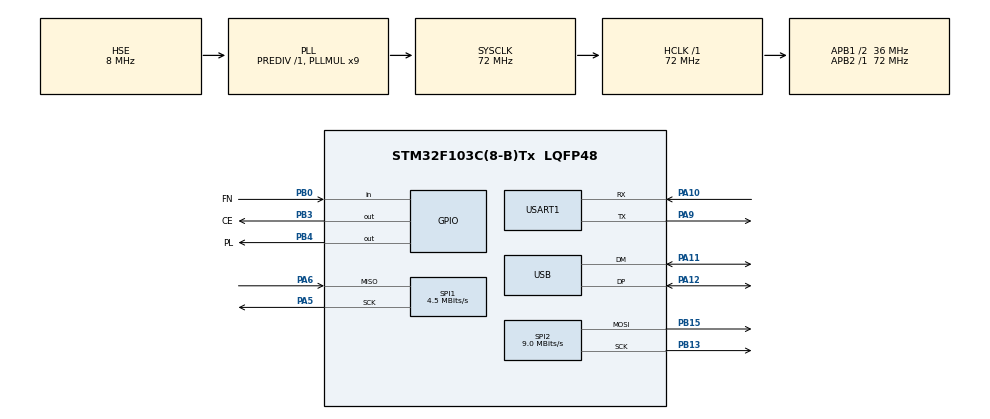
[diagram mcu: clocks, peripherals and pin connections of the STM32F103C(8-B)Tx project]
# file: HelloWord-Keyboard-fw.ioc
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Dma.Request0=SPI2_TX
Dma.Request1=SPI1_RX
Dma.SPI1_RX.1.Direction=DMA_PERIPH_TO_MEMORY
Dma.SPI1_RX.1.Instance=DMA1_Channel2
Dma.SPI1_RX.1.MemDataAlignment=DMA_MDATAALIGN_BYTE
Dma.SPI1_RX.1.MemInc=DMA_MINC_ENABLE
Dma.SPI1_RX.1.Mode=DMA_NORMAL
Dma.SPI1_RX.1.PeriphDataAlignment=DMA_PDATAALIGN_BYTE
Dma.SPI1_RX.1.PeriphInc=DMA_PINC_DISABLE
Dma.SPI1_RX.1.Priority=DMA_PRIORITY_MEDIUM
Dma.SPI2_TX.0.Direction=DMA_MEMORY_TO_PERIPH
Dma.SPI2_TX.0.Instance=DMA1_Channel5
Dma.SPI2_TX.0.MemDataAlignment=DMA_MDATAALIGN_BYTE
Dma.SPI2_TX.0.MemInc=DMA_MINC_ENABLE
Dma.SPI2_TX.0.Mode=DMA_NORMAL
Dma.SPI2_TX.0.PeriphDataAlignment=DMA_PDATAALIGN_BYTE
Dma.SPI2_TX.0.PeriphInc=DMA_PINC_DISABLE
Dma.SPI2_TX.0.Priority=DMA_PRIORITY_MEDIUM
Mcu.Family=STM32F1
Mcu.Name=STM32F103C(8-B)Tx
Mcu.Package=LQFP48
NVIC.DMA1_Channel2_IRQn=true\:2\:0\:true\:false\:true\:false\:true\:true
NVIC.DMA1_Channel5_IRQn=true\:2\:1\:true\:false\:true\:false\:true\:true
NVIC.PVD_IRQn=true\:0\:0\:false\:false\:true\:true\:true\:true
NVIC.PriorityGroup=NVIC_PRIORITYGROUP_2
NVIC.SPI1_IRQn=true\:1\:0\:true\:false\:true\:true\:true\:true
NVIC.SPI2_IRQn=true\:1\:1\:true\:false\:true\:true\:true\:true
NVIC.TIM4_IRQn=true\:0\:1\:false\:false\:true\:true\:true\:true
NVIC.USART1_IRQn=true\:0\:0\:true\:false\:true\:true\:true\:true
NVIC.USB_LP_CAN1_RX0_IRQn=true\:0\:0\:false\:false\:true\:false\:true\:true
PA10.Mode=Asynchronous
PA10.Signal=USART1_RX
PA11.Mode=Device
PA11.Signal=USB_DM
PA12.Mode=Device
PA12.Signal=USB_DP
PA13.Mode=Serial_Wire
PA13.Signal=SYS_JTMS-SWDIO
PA14.Mode=Serial_Wire
PA14.Signal=SYS_JTCK-SWCLK
PA5.Mode=RX_Only_Simplex_Unidirect_Master
PA5.Signal=SPI1_SCK
PA6.Mode=RX_Only_Simplex_Unidirect_Master
PA6.Signal=SPI1_MISO
PA9.Mode=Asynchronous
PA9.Signal=USART1_TX
PB0.GPIO_Label=FN
PB0.Signal=GPIO_Input
PB13.Mode=TX_Only_Simplex_Unidirect_Master
PB13.Signal=SPI2_SCK
PB15.Mode=TX_Only_Simplex_Unidirect_Master
PB15.Signal=SPI2_MOSI
PB3.GPIO_Label=CE
PB3.Signal=GPIO_Output
PB4.GPIO_Label=PL
PB4.Signal=GPIO_Output
PD0-OSC_IN.Mode=HSE-External-Oscillator
PD0-OSC_IN.Signal=RCC_OSC_IN
PD1-OSC_OUT.Mode=HSE-External-Oscillator
PD1-OSC_OUT.Signal=RCC_OSC_OUT
ProjectManager.HeapSize=0x200
ProjectManager.StackSize=0x800
ProjectManager.TargetToolchain=SW4STM32
RCC.AHBFreq_Value=72000000
RCC.APB1CLKDivider=RCC_HCLK_DIV2
RCC.APB1Freq_Value=36000000
RCC.APB1TimFreq_Value=72000000
RCC.APB2Freq_Value=72000000
RCC.APB2TimFreq_Value=72000000
RCC.HCLKFreq_Value=72000000
RCC.PLLMUL=RCC_PLL_MUL9
RCC.SYSCLKFreq_VALUE=72000000
RCC.SYSCLKSource=RCC_SYSCLKSOURCE_PLLCLK
RCC.USBFreq_Value=48000000
RCC.USBPrescaler=RCC_USBCLKSOURCE_PLL_DIV1_5
SPI1.BaudRatePrescaler=SPI_BAUDRATEPRESCALER_16
SPI1.CLKPhase=SPI_PHASE_1EDGE
SPI1.CLKPolarity=SPI_POLARITY_HIGH
SPI1.CalculateBaudRate=4.5 MBits/s
SPI1.Direction=SPI_DIRECTION_2LINES_RXONLY
SPI1.Mode=SPI_MODE_MASTER
SPI1.VirtualType=VM_MASTER
SPI2.BaudRatePrescaler=SPI_BAUDRATEPRESCALER_4
SPI2.CLKPhase=SPI_PHASE_2EDGE
SPI2.CalculateBaudRate=9.0 MBits/s
SPI2.Direction=SPI_DIRECTION_2LINES
SPI2.Mode=SPI_MODE_MASTER
SPI2.VirtualType=VM_MASTER
TIM4.Period=999
TIM4.Prescaler=71
USART1.VirtualMode=VM_ASYNC
USB_DEVICE.CLASS_NAME_FS=CUSTOM_HID
USB_DEVICE.CUSTOM_HID_FS_BINTERVAL=0x1
USB_DEVICE.MANUFACTURER_STRING=Pengzhihui
USB_DEVICE.PID_CUSTOMHID_FS=61699
USB_DEVICE.PRODUCT_STRING_CUSTOMHID_FS=HelloWord Smart Keyboard
USB_DEVICE.USBD_CUSTOMHID_OUTREPORT_BUF_SIZE=64
USB_DEVICE.USBD_CUSTOM_HID_REPORT_DESC_SIZE=39
USB_DEVICE.VID=4097
USB_DEVICE.VirtualMode=CustomHid
USB_DEVICE.VirtualModeFS=Custom_Hid_FS
VP_TIM4_VS_ClockSourceINT.Mode=Internal
VP_USB_DEVICE_VS_USB_DEVICE_CUSTOM_HID_FS.Mode=CUSTOM_HID_FS
board=custom

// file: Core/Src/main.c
/* USER CODE BEGIN Header */
/**
  ******************************************************************************
  * @file           : main.c
  * @brief          : Main program body
  ******************************************************************************
  * @attention
  *
  * <h2><center>&copy; Copyright (c) 2022 STMicroelectronics.
  * All rights reserved.</center></h2>
  *
  * This software component is licensed by ST under Ultimate Liberty license
  * SLA0044, the "License"; You may not use this file except in compliance with
  * the License. You may obtain a copy of the License at:
  *                             www.st.com/SLA0044
  *
  ******************************************************************************
  */
/* USER CODE END Header */
#include "main.h"
#include "dma.h"
#include "spi.h"
#include "tim.h"
#include "usart.h"
#include "usb_device.h"
#include "gpio.h"
#include "iwdg.h"

/* USER CODE BEGIN Includes */
#include "common_inc.h"
/* USER CODE END Includes */

void SystemClock_Config(void);

int main(void)
{
  /* USER CODE BEGIN 1 */
HAL_RCC_DeInit();
  /* USER CODE END 1 */

  /* MCU Configuration--------------------------------------------------------*/

  /* Reset of all peripherals, Initializes the Flash interface and the Systick. */
  HAL_Init();

  /* Configure the system clock */
  SystemClock_Config();

  /* Initialize all configured peripherals */
  MX_GPIO_Init();
  MX_DMA_Init();
  MX_SPI1_Init();
  MX_TIM4_Init();
  MX_USART1_UART_Init();
  MX_USB_DEVICE_Init();
  MX_SPI2_Init();
  MX_IWDG_Init();
  /* USER CODE BEGIN 2 */
  Main();
  /* USER CODE END 2 */

  /* Infinite loop */
    while (1)
    {

    }
}

void SystemClock_Config(void)
{
  RCC_OscInitTypeDef RCC_OscInitStruct = {0};
  RCC_ClkInitTypeDef RCC_ClkInitStruct = {0};
  RCC_PeriphCLKInitTypeDef PeriphClkInit = {0};

  /** Initializes the RCC Oscillators according to the specified parameters
  * in the RCC_OscInitTypeDef structure.
  */
  RCC_OscInitStruct.OscillatorType = RCC_OSCILLATORTYPE_HSE;
  RCC_OscInitStruct.HSEState = RCC_HSE_ON;
  RCC_OscInitStruct.HSEPredivValue = RCC_HSE_PREDIV_DIV1;
  RCC_OscInitStruct.HSIState = RCC_HSI_ON;
  RCC_OscInitStruct.PLL.PLLState = RCC_PLL_ON;
  RCC_OscInitStruct.PLL.PLLSource = RCC_PLLSOURCE_HSE;
  RCC_OscInitStruct.PLL.PLLMUL = RCC_PLL_MUL9;
  if (HAL_RCC_OscConfig(&RCC_OscInitStruct) != HAL_OK)
  {
    Error_Handler();
  }
  /** Initializes the CPU, AHB and APB buses clocks
  */
  RCC_ClkInitStruct.ClockType = RCC_CLOCKTYPE_HCLK|RCC_CLOCKTYPE_SYSCLK
                              |RCC_CLOCKTYPE_PCLK1|RCC_CLOCKTYPE_PCLK2;
  RCC_ClkInitStruct.SYSCLKSource = RCC_SYSCLKSOURCE_PLLCLK;
  RCC_ClkInitStruct.AHBCLKDivider = RCC_SYSCLK_DIV1;
  RCC_ClkInitStruct.APB1CLKDivider = RCC_HCLK_DIV2;
  RCC_ClkInitStruct.APB2CLKDivider = RCC_HCLK_DIV1;

  if (HAL_RCC_ClockConfig(&RCC_ClkInitStruct, FLASH_LATENCY_2) != HAL_OK)
  {
    Error_Handler();
  }
  PeriphClkInit.PeriphClockSelection = RCC_PERIPHCLK_USB;
  PeriphClkInit.UsbClockSelection = RCC_USBCLKSOURCE_PLL_DIV1_5;
  if (HAL_RCCEx_PeriphCLKConfig(&PeriphClkInit) != HAL_OK)
  {
    Error_Handler();
  }
}

void Error_Handler(void)
{
  /* USER CODE BEGIN Error_Ha3ndler_Debug */
    /* User can add his own implementation to report the HAL error return state */
    __disable_irq();
    while (1)
    {
    }
  /* USER CODE END Error_Handler_Debug */
}

/************************ (C) COPYRIGHT STMicroelectronics *****END OF FILE****/
